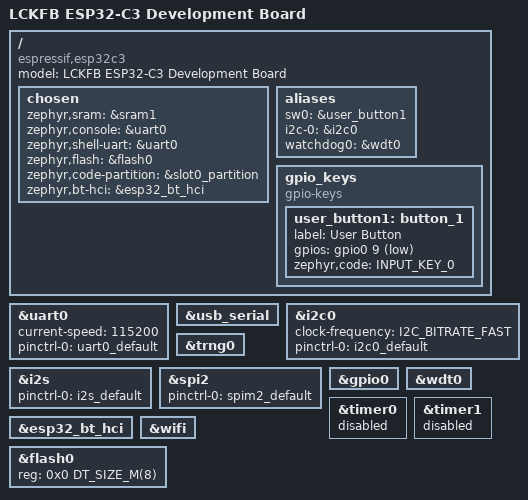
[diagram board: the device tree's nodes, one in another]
/*
 * Copyright (c) 2025 LCKFB
 *
 * SPDX-License-Identifier: Apache-2.0
 */

/dts-v1/;

#include <espressif/esp32c3/esp32c3_common.dtsi>
#include "esp32c3_lckfb-pinctrl.dtsi"
#include <zephyr/dt-bindings/input/input-event-codes.h>
#include <espressif/partitions_0x0_default_8M.dtsi>

/ {
	model = "LCKFB ESP32-C3 Development Board";
	compatible = "espressif,esp32c3";

	chosen {
		zephyr,sram = &sram1;
		zephyr,console = &uart0;
		zephyr,shell-uart = &uart0;
		zephyr,flash = &flash0;
		zephyr,code-partition = &slot0_partition;
		zephyr,bt-hci = &esp32_bt_hci;
	};

	aliases {
		sw0 = &user_button1;
		i2c-0 = &i2c0;
		watchdog0 = &wdt0;
	};

	gpio_keys {
		compatible = "gpio-keys";

		user_button1: button_1 {
			label = "User Button";
			gpios = <&gpio0 9 (GPIO_PULL_UP | GPIO_ACTIVE_LOW)>;
			zephyr,code = <INPUT_KEY_0>;
		};
	};
};

&uart0 {
	status = "okay";
	current-speed = <115200>;
	pinctrl-0 = <&uart0_default>;
	pinctrl-names = "default";
};

&usb_serial {
	status = "okay";
};

&i2c0 {
	status = "okay";
	clock-frequency = <I2C_BITRATE_FAST>;
	pinctrl-0 = <&i2c0_default>;
	pinctrl-names = "default";
};

&i2s {
	pinctrl-0 = <&i2s_default>;
	pinctrl-names = "default";
};

&trng0 {
	status = "okay";
};

&spi2 {
	#address-cells = <1>;
	#size-cells = <0>;
	status = "okay";
	pinctrl-0 = <&spim2_default>;
	pinctrl-names = "default";
};

&gpio0 {
	status = "okay";
};

&wdt0 {
	status = "okay";
};

&timer0 {
	status = "disabled";
};

&timer1 {
	status = "disabled";
};

&esp32_bt_hci {
	status = "okay";
};

&wifi {
	status = "okay";
};

/* Override flash size to 8MB
 * esp32c3_common.dtsi does not define a default flash size,
 * and this board uses 8MB flash, so we need to specify it explicitly.
 */
&flash0 {
	reg = <0x0 DT_SIZE_M(8)>;
};
